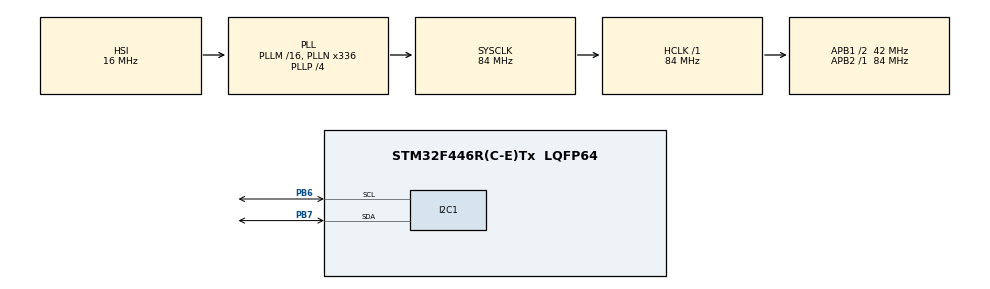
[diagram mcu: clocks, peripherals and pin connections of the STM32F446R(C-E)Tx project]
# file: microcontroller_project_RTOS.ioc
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FREERTOS.Tasks01=Task1,40,1024,StartTask1,Default,NULL,Dynamic,NULL,NULL
FREERTOS.configTOTAL_HEAP_SIZE=24 * 1024
Mcu.Family=STM32F4
Mcu.Name=STM32F446R(C-E)Tx
Mcu.Package=LQFP64
NVIC.PriorityGroup=NVIC_PRIORITYGROUP_0
NVIC.TIM6_DAC_IRQn=true\:0\:0\:false\:false\:true\:false\:false\:true
NVIC.TimeBase=TIM6_DAC_IRQn
NVIC.TimeBaseIP=TIM6
PA13.Mode=Trace_Asynchronous_SW
PA13.Signal=SYS_JTMS-SWDIO
PA14.Mode=Trace_Asynchronous_SW
PA14.Signal=SYS_JTCK-SWCLK
PB3.Mode=Trace_Asynchronous_SW
PB3.Signal=SYS_JTDO-SWO
PB6.Mode=I2C
PB6.Signal=I2C1_SCL
PB7.Mode=I2C
PB7.Signal=I2C1_SDA
ProjectManager.HeapSize=0x200
ProjectManager.StackSize=0x400
ProjectManager.TargetToolchain=STM32CubeIDE
RCC.48MHZClocksFreq_Value=84000000
RCC.AHBFreq_Value=84000000
RCC.APB1CLKDivider=RCC_HCLK_DIV2
RCC.APB1Freq_Value=42000000
RCC.APB1TimFreq_Value=84000000
RCC.APB2Freq_Value=84000000
RCC.APB2TimFreq_Value=84000000
RCC.CortexFreq_Value=84000000
RCC.FLatency-AdvancedSettings=FLASH_LATENCY_2
RCC.HCLKFreq_Value=84000000
RCC.HSE_VALUE=8000000
RCC.HSI_VALUE=16000000
RCC.PLLN=336
RCC.PLLP=RCC_PLLP_DIV4
RCC.SYSCLKFreq_VALUE=84000000
RCC.SYSCLKSource=RCC_SYSCLKSOURCE_PLLCLK
RCC.USBFreq_Value=168000000
RCC.VCOOutputFreq_Value=336000000
VP_FREERTOS_VS_CMSIS_V2.Mode=CMSIS_V2
VP_SYS_VS_tim6.Mode=TIM6
board=NUCLEO-F446RE

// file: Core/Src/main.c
/* USER CODE BEGIN Header */
/**
  ******************************************************************************
  * @file           : main.c
  * @brief          : Main program body
  ******************************************************************************
  * @attention
  *
  * <h2><center>&copy; Copyright (c) 2025 STMicroelectronics.
  * All rights reserved.</center></h2>
  *
  * This software component is licensed by ST under BSD 3-Clause license,
  * the "License"; You may not use this file except in compliance with the
  * License. You may obtain a copy of the License at:
  *                        opensource.org/licenses/BSD-3-Clause
  *
  ******************************************************************************
  */
/* USER CODE END Header */
#include "main.h"
#include "cmsis_os.h"
#include "i2c.h"
#include "gpio.h"

/* USER CODE BEGIN PV */
/*BMP280_HandleTypedef bmp280;
float temperature, pressure, humidity;
*/
/* USER CODE END PV */

void SystemClock_Config(void);
void MX_FREERTOS_Init(void);

int main(void)
{

  /* MCU Configuration--------------------------------------------------------*/

  /* Reset of all peripherals, Initializes the Flash interface and the Systick. */
  HAL_Init();

  /* Configure the system clock */
  SystemClock_Config();

  /* Initialize all configured peripherals */
  MX_GPIO_Init();
  MX_I2C1_Init();
  /* USER CODE BEGIN 2 */
  LD2_Config();
  /* USER CODE END 2 */

  /* Init scheduler */
  osKernelInitialize();  /* Call init function for freertos objects (in freertos.c) */
  MX_FREERTOS_Init();
  /* Start scheduler */
  osKernelStart();

  /* We should never get here as control is now taken by the scheduler */
  /* Infinite loop */
  while (1)
  {

  }
}

void SystemClock_Config(void)
{
  RCC_OscInitTypeDef RCC_OscInitStruct = {0};
  RCC_ClkInitTypeDef RCC_ClkInitStruct = {0};

  /** Configure the main internal regulator output voltage
  */
  __HAL_RCC_PWR_CLK_ENABLE();
  __HAL_PWR_VOLTAGESCALING_CONFIG(PWR_REGULATOR_VOLTAGE_SCALE3);
  /** Initializes the RCC Oscillators according to the specified parameters
  * in the RCC_OscInitTypeDef structure.
  */
  RCC_OscInitStruct.OscillatorType = RCC_OSCILLATORTYPE_HSI;
  RCC_OscInitStruct.HSIState = RCC_HSI_ON;
  RCC_OscInitStruct.HSICalibrationValue = RCC_HSICALIBRATION_DEFAULT;
  RCC_OscInitStruct.PLL.PLLState = RCC_PLL_ON;
  RCC_OscInitStruct.PLL.PLLSource = RCC_PLLSOURCE_HSI;
  RCC_OscInitStruct.PLL.PLLM = 16;
  RCC_OscInitStruct.PLL.PLLN = 336;
  RCC_OscInitStruct.PLL.PLLP = RCC_PLLP_DIV4;
  RCC_OscInitStruct.PLL.PLLQ = 2;
  RCC_OscInitStruct.PLL.PLLR = 2;
  if (HAL_RCC_OscConfig(&RCC_OscInitStruct) != HAL_OK)
  {
    Error_Handler();
  }
  /** Initializes the CPU, AHB and APB buses clocks
  */
  RCC_ClkInitStruct.ClockType = RCC_CLOCKTYPE_HCLK|RCC_CLOCKTYPE_SYSCLK
                              |RCC_CLOCKTYPE_PCLK1|RCC_CLOCKTYPE_PCLK2;
  RCC_ClkInitStruct.SYSCLKSource = RCC_SYSCLKSOURCE_PLLCLK;
  RCC_ClkInitStruct.AHBCLKDivider = RCC_SYSCLK_DIV1;
  RCC_ClkInitStruct.APB1CLKDivider = RCC_HCLK_DIV2;
  RCC_ClkInitStruct.APB2CLKDivider = RCC_HCLK_DIV1;

  if (HAL_RCC_ClockConfig(&RCC_ClkInitStruct, FLASH_LATENCY_2) != HAL_OK)
  {
    Error_Handler();
  }
}

/* USER CODE BEGIN 4 */
void LD2_Config(){
	RCC->AHB1ENR |= RCC_AHB1ENR_GPIOAEN;

	GPIOA->MODER |= GPIO_MODER_MODE5_0;
	GPIOA->MODER &= ~(GPIO_MODER_MODE5_1);

	GPIOA->OTYPER &= ~(GPIO_OTYPER_OT5);

	GPIOA->OSPEEDR &= ~(GPIO_OSPEEDER_OSPEEDR5);

	GPIOA->PUPDR &= ~(GPIO_PUPDR_PUPD5);
}
/* USER CODE END 4 */

void HAL_TIM_PeriodElapsedCallback(TIM_HandleTypeDef *htim)
{
  if (htim->Instance == TIM6) {
    HAL_IncTick();
  }
}

void Error_Handler(void)
{
}

/************************ (C) COPYRIGHT STMicroelectronics *****END OF FILE****/

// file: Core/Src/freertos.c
/* USER CODE BEGIN Header */
/**
  ******************************************************************************
  * File Name          : freertos.c
  * Description        : Code for freertos applications
  ******************************************************************************
  * @attention
  *
  * <h2><center>&copy; Copyright (c) 2025 STMicroelectronics.
  * All rights reserved.</center></h2>
  *
  * This software component is licensed by ST under Ultimate Liberty license
  * SLA0044, the "License"; You may not use this file except in compliance with
  * the License. You may obtain a copy of the License at:
  *                             www.st.com/SLA0044
  *
  ******************************************************************************
  */
/* USER CODE END Header */

#include "FreeRTOS.h"
#include "task.h"
#include "main.h"
#include "cmsis_os.h"

/* USER CODE BEGIN Variables */
//extern BMP280_HandleTypedef bmp280;
//extern float temperature, pressure, humidity;

/* USER CODE END Variables */
/* Definitions for Task1 */
osThreadId_t Task1Handle;
const osThreadAttr_t Task1_attributes = {
  .name = "Task1",
  .priority = (osPriority_t) osPriorityHigh,
  .stack_size = 1024 * 4
};

void StartTask1(void *argument);

void MX_FREERTOS_Init(void); /* (MISRA C 2004 rule 8.1) */

void MX_FREERTOS_Init(void) {

  /* Create the thread(s) */
  /* creation of Task1 */
  Task1Handle = osThreadNew(StartTask1, NULL, &Task1_attributes);

}

void StartTask1(void *argument)
{
  /* USER CODE BEGIN StartTask1 */
	volatile uint8_t count;
	/* Infinite loop */
  for(;;)
  {
	  count++;
    osDelay(100);
  }
  /* USER CODE END StartTask1 */
}

/************************ (C) COPYRIGHT STMicroelectronics *****END OF FILE****/
